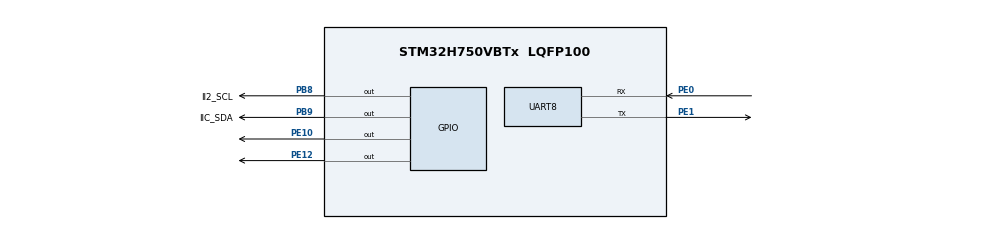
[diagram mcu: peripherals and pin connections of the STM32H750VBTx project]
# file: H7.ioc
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CORTEX_M7.default_mode_Activation=1
Dma.Request0=UART8_RX
Dma.Request1=UART8_TX
Dma.UART8_RX.0.Direction=DMA_PERIPH_TO_MEMORY
Dma.UART8_RX.0.EventEnable=DISABLE
Dma.UART8_RX.0.FIFOMode=DMA_FIFOMODE_DISABLE
Dma.UART8_RX.0.Instance=DMA1_Stream0
Dma.UART8_RX.0.MemDataAlignment=DMA_MDATAALIGN_BYTE
Dma.UART8_RX.0.MemInc=DMA_MINC_ENABLE
Dma.UART8_RX.0.Mode=DMA_NORMAL
Dma.UART8_RX.0.PeriphDataAlignment=DMA_PDATAALIGN_BYTE
Dma.UART8_RX.0.PeriphInc=DMA_PINC_DISABLE
Dma.UART8_RX.0.Polarity=HAL_DMAMUX_REQ_GEN_RISING
Dma.UART8_RX.0.Priority=DMA_PRIORITY_LOW
Dma.UART8_RX.0.RequestNumber=1
Dma.UART8_RX.0.SignalID=NONE
Dma.UART8_RX.0.SyncEnable=DISABLE
Dma.UART8_RX.0.SyncPolarity=HAL_DMAMUX_SYNC_NO_EVENT
Dma.UART8_RX.0.SyncRequestNumber=1
Dma.UART8_RX.0.SyncSignalID=NONE
Dma.UART8_TX.1.Direction=DMA_MEMORY_TO_PERIPH
Dma.UART8_TX.1.EventEnable=DISABLE
Dma.UART8_TX.1.FIFOMode=DMA_FIFOMODE_DISABLE
Dma.UART8_TX.1.Instance=DMA1_Stream1
Dma.UART8_TX.1.MemDataAlignment=DMA_MDATAALIGN_BYTE
Dma.UART8_TX.1.MemInc=DMA_MINC_ENABLE
Dma.UART8_TX.1.Mode=DMA_NORMAL
Dma.UART8_TX.1.PeriphDataAlignment=DMA_PDATAALIGN_BYTE
Dma.UART8_TX.1.PeriphInc=DMA_PINC_DISABLE
Dma.UART8_TX.1.Polarity=HAL_DMAMUX_REQ_GEN_RISING
Dma.UART8_TX.1.Priority=DMA_PRIORITY_LOW
Dma.UART8_TX.1.RequestNumber=1
Dma.UART8_TX.1.SignalID=NONE
Dma.UART8_TX.1.SyncEnable=DISABLE
Dma.UART8_TX.1.SyncPolarity=HAL_DMAMUX_SYNC_NO_EVENT
Dma.UART8_TX.1.SyncRequestNumber=1
Dma.UART8_TX.1.SyncSignalID=NONE
FREERTOS.BinarySemaphores01=ms5837BinarySem,Dynamic,NULL
FREERTOS.Queues01=rxQueue,3,rxStruct,0,Dynamic,NULL,NULL;txQueue,3,txStruct,0,Dynamic,NULL,NULL
FREERTOS.Tasks01=defaultTask,24,128,StartDefaultTask,Default,NULL,Dynamic,NULL,NULL;cmdTask,40,256,CmdTask,As external,NULL,Dynamic,NULL,NULL;ms5837Task,8,128,Ms5837Task,As external,NULL,Dynamic,NULL,NULL;txTask,40,128,TxTask,As external,NULL,Dynamic,NULL,NULL
FREERTOS.configTOTAL_HEAP_SIZE=15360
Mcu.Family=STM32H7
Mcu.Name=STM32H750VBTx
Mcu.Package=LQFP100
NVIC.DMA1_Stream0_IRQn=true\:5\:0\:false\:false\:true\:true\:false\:true\:true
NVIC.DMA1_Stream1_IRQn=true\:5\:0\:false\:false\:true\:true\:false\:true\:true
NVIC.PriorityGroup=NVIC_PRIORITYGROUP_4
NVIC.TIM17_IRQn=true\:15\:0\:false\:false\:true\:false\:false\:true\:true
NVIC.TimeBase=TIM17_IRQn
NVIC.TimeBaseIP=TIM17
NVIC.UART8_IRQn=true\:5\:0\:false\:false\:true\:true\:true\:true\:true
PB8.GPIO_Label=II2_SCL
PB8.GPIO_ModeDefaultOutputPP=GPIO_MODE_OUTPUT_PP
PB8.GPIO_PuPd=GPIO_PULLUP
PB8.GPIO_Speed=GPIO_SPEED_FREQ_VERY_HIGH
PB8.PinState=GPIO_PIN_SET
PB8.Signal=GPIO_Output
PB9.GPIO_Label=IIC_SDA
PB9.GPIO_PuPd=GPIO_PULLUP
PB9.GPIO_Speed=GPIO_SPEED_FREQ_VERY_HIGH
PB9.PinState=GPIO_PIN_SET
PB9.Signal=GPIO_Output
PC14-OSC32_IN\ (OSC32_IN).Mode=LSE-External-Oscillator
PC14-OSC32_IN\ (OSC32_IN).Signal=RCC_OSC32_IN
PC15-OSC32_OUT\ (OSC32_OUT).Mode=LSE-External-Oscillator
PC15-OSC32_OUT\ (OSC32_OUT).Signal=RCC_OSC32_OUT
PE0.Mode=Asynchronous
PE0.Signal=UART8_RX
PE1.Mode=Asynchronous
PE1.Signal=UART8_TX
PE10.Signal=GPIO_Output
PE12.Signal=GPIO_Output
PH0-OSC_IN\ (PH0).Mode=HSE-External-Oscillator
PH0-OSC_IN\ (PH0).Signal=RCC_OSC_IN
PH1-OSC_OUT\ (PH1).Mode=HSE-External-Oscillator
PH1-OSC_OUT\ (PH1).Signal=RCC_OSC_OUT
ProjectManager.HeapSize=0x1000
ProjectManager.StackSize=0x400
ProjectManager.TargetToolchain=MDK-ARM V5.32
RCC.ADCFreq_Value=50390625
RCC.APB1Freq_Value=120000000
RCC.APB2Freq_Value=120000000
RCC.APB3Freq_Value=120000000
RCC.APB4Freq_Value=120000000
RCC.CortexFreq_Value=480000000
RCC.D1PPRE=RCC_APB3_DIV2
RCC.D2PPRE1=RCC_APB1_DIV2
RCC.D2PPRE2=RCC_APB2_DIV2
RCC.D3PPRE=RCC_APB4_DIV2
RCC.DIVM1=5
RCC.DIVN1=192
RCC.DIVQ1=5
RCC.HCLKFreq_Value=240000000
RCC.HPRE=RCC_HCLK_DIV2
RCC.PLLFRACN=0
RCC.PLLSourceVirtual=RCC_PLLSOURCE_HSE
RCC.SYSCLKFreq_VALUE=480000000
RCC.SYSCLKSource=RCC_SYSCLKSOURCE_PLLCLK
RCC.USBFreq_Value=192000000
TIM3.Prescaler=239
VP_FREERTOS_VS_CMSIS_V2.Mode=CMSIS_V2
VP_SYS_VS_tim17.Mode=TIM17
VP_TIM3_VS_ClockSourceINT.Mode=Internal
board=custom

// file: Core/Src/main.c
/* USER CODE BEGIN Header */
/**
  ******************************************************************************
  * @file           : main.c
  * @brief          : Main program body
  ******************************************************************************
  * @attention
  *
  * Copyright (c) 2024 STMicroelectronics.
  * All rights reserved.
  *
  * This software is licensed under terms that can be found in the LICENSE file
  * in the root directory of this software component.
  * If no LICENSE file comes with this software, it is provided AS-IS.
  *
  ******************************************************************************
  */
/* USER CODE END Header */
#include "main.h"
#include "cmsis_os.h"
#include "dma.h"
#include "tim.h"
#include "usart.h"
#include "gpio.h"

void SystemClock_Config(void);
static void MPU_Config(void);
void MX_FREERTOS_Init(void);

int main(void)
{

  /* MPU Configuration--------------------------------------------------------*/
  MPU_Config();

  /* MCU Configuration--------------------------------------------------------*/

  /* Reset of all peripherals, Initializes the Flash interface and the Systick. */
  HAL_Init();

  /* Configure the system clock */
  SystemClock_Config();

  /* Initialize all configured peripherals */
  MX_GPIO_Init();
  MX_DMA_Init();
  MX_TIM3_Init();
  MX_UART8_Init();

  /* Init scheduler */
  osKernelInitialize();

  /* Call init function for freertos objects (in cmsis_os2.c) */
  MX_FREERTOS_Init();

  /* Start scheduler */
  osKernelStart();

  /* We should never get here as control is now taken by the scheduler */

  /* Infinite loop */
  while (1)
  {

  }
}

void SystemClock_Config(void)
{
  RCC_OscInitTypeDef RCC_OscInitStruct = {0};
  RCC_ClkInitTypeDef RCC_ClkInitStruct = {0};

  /** Supply configuration update enable
  */
  HAL_PWREx_ConfigSupply(PWR_LDO_SUPPLY);

  /** Configure the main internal regulator output voltage
  */
  __HAL_PWR_VOLTAGESCALING_CONFIG(PWR_REGULATOR_VOLTAGE_SCALE1);

  while(!__HAL_PWR_GET_FLAG(PWR_FLAG_VOSRDY)) {}

  __HAL_RCC_SYSCFG_CLK_ENABLE();
  __HAL_PWR_VOLTAGESCALING_CONFIG(PWR_REGULATOR_VOLTAGE_SCALE0);

  while(!__HAL_PWR_GET_FLAG(PWR_FLAG_VOSRDY)) {}

  /** Initializes the RCC Oscillators according to the specified parameters
  * in the RCC_OscInitTypeDef structure.
  */
  RCC_OscInitStruct.OscillatorType = RCC_OSCILLATORTYPE_HSE;
  RCC_OscInitStruct.HSEState = RCC_HSE_ON;
  RCC_OscInitStruct.PLL.PLLState = RCC_PLL_ON;
  RCC_OscInitStruct.PLL.PLLSource = RCC_PLLSOURCE_HSE;
  RCC_OscInitStruct.PLL.PLLM = 5;
  RCC_OscInitStruct.PLL.PLLN = 192;
  RCC_OscInitStruct.PLL.PLLP = 2;
  RCC_OscInitStruct.PLL.PLLQ = 5;
  RCC_OscInitStruct.PLL.PLLR = 2;
  RCC_OscInitStruct.PLL.PLLRGE = RCC_PLL1VCIRANGE_2;
  RCC_OscInitStruct.PLL.PLLVCOSEL = RCC_PLL1VCOWIDE;
  RCC_OscInitStruct.PLL.PLLFRACN = 0;
  if (HAL_RCC_OscConfig(&RCC_OscInitStruct) != HAL_OK)
  {
    Error_Handler();
  }

  /** Initializes the CPU, AHB and APB buses clocks
  */
  RCC_ClkInitStruct.ClockType = RCC_CLOCKTYPE_HCLK|RCC_CLOCKTYPE_SYSCLK
                              |RCC_CLOCKTYPE_PCLK1|RCC_CLOCKTYPE_PCLK2
                              |RCC_CLOCKTYPE_D3PCLK1|RCC_CLOCKTYPE_D1PCLK1;
  RCC_ClkInitStruct.SYSCLKSource = RCC_SYSCLKSOURCE_PLLCLK;
  RCC_ClkInitStruct.SYSCLKDivider = RCC_SYSCLK_DIV1;
  RCC_ClkInitStruct.AHBCLKDivider = RCC_HCLK_DIV2;
  RCC_ClkInitStruct.APB3CLKDivider = RCC_APB3_DIV2;
  RCC_ClkInitStruct.APB1CLKDivider = RCC_APB1_DIV2;
  RCC_ClkInitStruct.APB2CLKDivider = RCC_APB2_DIV2;
  RCC_ClkInitStruct.APB4CLKDivider = RCC_APB4_DIV2;

  if (HAL_RCC_ClockConfig(&RCC_ClkInitStruct, FLASH_LATENCY_4) != HAL_OK)
  {
    Error_Handler();
  }
}

 /* MPU Configuration */

void MPU_Config(void)
{
  MPU_Region_InitTypeDef MPU_InitStruct = {0};

  /* Disables the MPU */
  HAL_MPU_Disable();

  /** Initializes and configures the Region and the memory to be protected
  */
  MPU_InitStruct.Enable = MPU_REGION_ENABLE;
  MPU_InitStruct.Number = MPU_REGION_NUMBER0;
  MPU_InitStruct.BaseAddress = 0x0;
  MPU_InitStruct.Size = MPU_REGION_SIZE_4GB;
  MPU_InitStruct.SubRegionDisable = 0x87;
  MPU_InitStruct.TypeExtField = MPU_TEX_LEVEL0;
  MPU_InitStruct.AccessPermission = MPU_REGION_NO_ACCESS;
  MPU_InitStruct.DisableExec = MPU_INSTRUCTION_ACCESS_DISABLE;
  MPU_InitStruct.IsShareable = MPU_ACCESS_SHAREABLE;
  MPU_InitStruct.IsCacheable = MPU_ACCESS_NOT_CACHEABLE;
  MPU_InitStruct.IsBufferable = MPU_ACCESS_NOT_BUFFERABLE;

  HAL_MPU_ConfigRegion(&MPU_InitStruct);
  /* Enables the MPU */
  HAL_MPU_Enable(MPU_PRIVILEGED_DEFAULT);

}

void HAL_TIM_PeriodElapsedCallback(TIM_HandleTypeDef *htim)
{
  if (htim->Instance == TIM17) {
    HAL_IncTick();
  }
}

void Error_Handler(void)
{
  __disable_irq();
  while (1)
  {
  }
}

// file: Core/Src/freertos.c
/* USER CODE BEGIN Header */
/**
  ******************************************************************************
  * File Name          : freertos.c
  * Description        : Code for freertos applications
  ******************************************************************************
  * @attention
  *
  * Copyright (c) 2024 STMicroelectronics.
  * All rights reserved.
  *
  * This software is licensed under terms that can be found in the LICENSE file
  * in the root directory of this software component.
  * If no LICENSE file comes with this software, it is provided AS-IS.
  *
  ******************************************************************************
  */
/* USER CODE END Header */

#include "FreeRTOS.h"
#include "task.h"
#include "main.h"
#include "cmsis_os.h"

/* USER CODE BEGIN Includes */
#include "usart.h"
#include "gpio.h"
#include "cmd.h"
#include "MS5837Task.h"
#include "MS5837.h"
#include <string.h>
#include <stdlib.h>
#include "usart.h"
/* USER CODE END Includes */

/* Definitions for defaultTask */
osThreadId_t defaultTaskHandle;
const osThreadAttr_t defaultTask_attributes = {
  .name = "defaultTask",
  .stack_size = 128 * 4,
  .priority = (osPriority_t) osPriorityNormal,
};
/* Definitions for cmdTask */
osThreadId_t cmdTaskHandle;
const osThreadAttr_t cmdTask_attributes = {
  .name = "cmdTask",
  .stack_size = 256 * 4,
  .priority = (osPriority_t) osPriorityHigh,
};
/* Definitions for ms5837Task */
osThreadId_t ms5837TaskHandle;
const osThreadAttr_t ms5837Task_attributes = {
  .name = "ms5837Task",
  .stack_size = 256 * 4,
  .priority = (osPriority_t) osPriorityLow,
};
/* Definitions for txTask */
osThreadId_t txTaskHandle;
const osThreadAttr_t txTask_attributes = {
  .name = "txTask",
  .stack_size = 256 * 4,
  .priority = (osPriority_t) osPriorityHigh,
};
/* Definitions for rxQueue */
osMessageQueueId_t rxQueueHandle;
const osMessageQueueAttr_t rxQueue_attributes = {
  .name = "rxQueue"
};
/* Definitions for txQueue */
osMessageQueueId_t txQueueHandle;
const osMessageQueueAttr_t txQueue_attributes = {
  .name = "txQueue"
};
/* Definitions for usart8Mutex */
osMutexId_t usart8MutexHandle;
const osMutexAttr_t usart8Mutex_attributes = {
  .name = "usart8Mutex"
};
/* Definitions for ms5837BinarySem */
osSemaphoreId_t ms5837BinarySemHandle;
const osSemaphoreAttr_t ms5837BinarySem_attributes = {
  .name = "ms5837BinarySem"
};

void StartDefaultTask(void *argument);
extern void CmdTask(void *argument);
extern void Ms5837Task(void *argument);
extern void TxTask(void *argument);

void MX_FREERTOS_Init(void); /* (MISRA C 2004 rule 8.1) */

void MX_FREERTOS_Init(void) {
  /* Create the mutex(es) */
  /* creation of usart8Mutex */
  usart8MutexHandle = osMutexNew(&usart8Mutex_attributes);

  /* Create the semaphores(s) */
  /* creation of ms5837BinarySem */
  ms5837BinarySemHandle = osSemaphoreNew(1, 0, &ms5837BinarySem_attributes);

  /* Create the queue(s) */
  /* creation of rxQueue */
  rxQueueHandle = osMessageQueueNew (3, sizeof(rxStruct), &rxQueue_attributes);

  /* creation of txQueue */
  txQueueHandle = osMessageQueueNew (3, sizeof(txStruct), &txQueue_attributes);

  /* Create the thread(s) */
  /* creation of defaultTask */
  defaultTaskHandle = osThreadNew(StartDefaultTask, NULL, &defaultTask_attributes);

  /* creation of cmdTask */
  cmdTaskHandle = osThreadNew(CmdTask, NULL, &cmdTask_attributes);

  /* creation of ms5837Task */
  ms5837TaskHandle = osThreadNew(Ms5837Task, NULL, &ms5837Task_attributes);

  /* creation of txTask */
  txTaskHandle = osThreadNew(TxTask, NULL, &txTask_attributes);

}

void StartDefaultTask(void *argument)
{
  /* USER CODE BEGIN StartDefaultTask */

  // unsigned char s_buf[]="hello world\r\n";
  /* Infinite loop */
  for(;;)
  {
    HAL_GPIO_TogglePin(GPIOE, GPIO_PIN_10);
    osDelay(60);
    // if(HAL_LOCKED == huart3.Lock)
    // {
    //   __HAL_UNLOCK(&huart3);      // 暴力解锁
    // }
  }
  /* USER CODE END StartDefaultTask */
}
